# TMS320F280049 register map
Vendor: Texas Instruments; Series: C2000 F28004x; File version: 0.2.0-generated
Registers are 16-bit, read-write, reset 0x0 unless marked. A register's access mark holds for its fields unless they carry their own. Offsets are from the block's base; [hi:lo] are bit positions; {n}, {i} and the like mark numbered series; 'fields as' and 'values as' point back to an identical list.

## EPWM1REGS — EPWM Registers
Base 0x00008000
Same registers: EPWM2REGS 0x00008200, EPWM3REGS 0x00008400, EPWM4REGS 0x00008600, EPWM5REGS 0x00008800, EPWM6REGS 0x00008A00, EPWM7REGS 0x00008C00, EPWM8REGS 0x00008E00
0x00 TBCTL — Time Base Control Register
  [15] FREE_SOFT — Emulation Mode Bits
  [13] PHSDIR — Phase Direction Bit
  [14:12] CLKDIV — Time Base Clock Pre-scaler
  [11:9] HSPCLKDIV — High Speed TBCLK Pre-scaler
  [6] SWFSYNC — Software Force Sync Pulse
  [6:5] SYNCOSEL — Sync Output Select
  [3] PRDLD — Active Period Load
  [2] PHSEN — Phase Load Enable
  [2:1] CTRMODE — Counter Mode
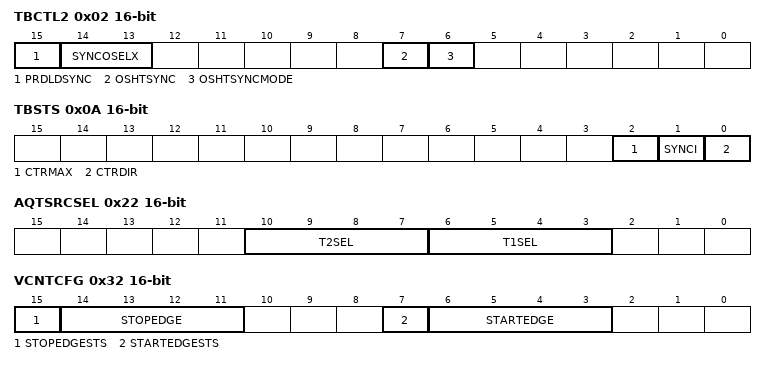
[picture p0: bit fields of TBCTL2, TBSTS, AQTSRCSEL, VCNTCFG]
0x02 TBCTL2 — Time Base Control Register 2
  [15] PRDLDSYNC — PRD Shadow to Active Load on SYNC Event
  [14:13] SYNCOSELX — Syncout selection
  [7] OSHTSYNC — One shot sync
  [6] OSHTSYNCMODE — One shot sync mode
0x08 TBCTR — Time Base Counter Register
  [15] TBCTR — Counter Value
0x0A TBSTS — Time Base Status Register
  [2] CTRMAX — Counter Max Latched Status
  [1] SYNCI — External Input Sync Status
  [0] CTRDIR — Counter Direction Status
0x10 CMPCTL — Counter Compare Control Register
  [14:13] LOADBSYNC — Active Compare B Load on SYNC
  [12:11] LOADASYNC — Active Compare A Load on SYNC
  [9] SHDWBFULL — Compare B Shadow Register Full Status
  [8] SHDWAFULL — Compare A Shadow Register Full Status
  [6] SHDWBMODE — Compare B Register Block Operating Mode
  [4] SHDWAMODE — Compare A Register Block Operating Mode
  [4:3] LOADBMODE — Active Compare B Load
  [2:1] LOADAMODE — Active Compare A Load
0x12 CMPCTL2 — Counter Compare Control Register 2
  [14:13] LOADDSYNC — Active Compare D Load on SYNC
  [12:11] LOADCSYNC — Active Compare C Load on SYNC
  [6] SHDWDMODE — Compare D Block Operating Mode
  [4] SHDWCMODE — Compare C Block Operating Mode
  [4:3] LOADDMODE — Active Compare D load
  [2:1] LOADCMODE — Active Compare C Load
0x18 DBCTL — Dead-Band Generator Control Register
  [15] HALFCYCLE — Half Cycle Clocking Enable
  [14] DEDB_MODE — Dead Band Dual-Edge B Mode Control
  [14:13] OUTSWAP — Dead Band Output Swap Control
  [11] SHDWDBFEDMODE — DBFED Block Operating Mode
  [10] SHDWDBREDMODE — DBRED Block Operating Mode
  [10:9] LOADFEDMODE — Active DBFED Load Mode
  [8:7] LOADREDMODE — Active DBRED Load Mode
  [6:5] IN_MODE — Dead Band Input Select Mode Control
  [4:3] POLSEL — Polarity Select Control
  [2:1] OUT_MODE — Dead Band Output Mode Control
0x1A DBCTL2 — Dead-Band Generator Control Register 2
  [2] SHDWDBCTLMODE — DBCTL Load mode Select
  [2:1] LOADDBCTLMODE — DBCTL Load from Shadow Mode Select
0x20 AQCTL — Action Qualifier Control Register
  [12:11] LDAQBSYNC — AQCTLB Register Load on SYNC
  [10:9] LDAQASYNC — AQCTLA Register Load on SYNC
  [6] SHDWAQBMODE — Action Qualifier B Operating Mode
  [4] SHDWAQAMODE — Action Qualifer A Operating Mode
  [4:3] LDAQBMODE — Action Qualifier B Load Select
  [2:1] LDAQAMODE — Action Qualifier A Load Select
0x22 AQTSRCSEL — Action Qualifier Trigger Event Source Select Register
  [10:7] T2SEL — T2 Event Source Select Bits
  [6:3] T1SEL — T1 Event Source Select Bits
0x28 PCCTL — PWM Chopper Control Register
  [12:10] CHPDUTY — Chopping clock Duty cycle
  [9:7] CHPFREQ — Chopping clock frequency
  [7:4] OSHTWTH — One-shot pulse width
  [0] CHPEN — PWM chopping enable
0x30 VCAPCTL — Valley Capture Control Register
  [10] EDGEFILTDLYSEL — Valley Switching Mode Delay Select
  [11:9] VDELAYDIV — Valley Delay Mode Divide Enable
  [6:4] TRIGSEL — Capture Trigger Select
  [1] VCAPSTART — Valley Capture Start
  [0] VCAPE — Valley Capture mode
0x32 VCNTCFG — Valley Counter Config Register
  [15] STOPEDGESTS — Stop Edge Status Bit
  [14:11] STOPEDGE — Counter Start Edge Selection
  [7] STARTEDGESTS — Start Edge Status Bit
  [6:3] STARTEDGE — Counter Start Edge Selection
0x40 HRCNFG — HRPWM Configuration Register
  [13:12] HRLOADB — ePWMxB Shadow Mode Select Bits
  [10] CTLMODEB — ePWMxB Control Mode Select Bits
  [10:9] EDGMODEB — ePWMxB Edge Mode Select Bits
  [7] SWAPAB — Swap EPWMA and EPWMB Outputs Bit
  [6] AUTOCONV — Autoconversion Bit
  [5] SELOUTB — EPWMB Output Selection Bit
  [5:4] HRLOAD — ePWMxA Shadow Mode Select Bits
  [2] CTLMODE — ePWMxA Control Mode Select Bits
  [2:1] EDGMODE — ePWMxA Edge Mode Select Bits
0x42 HRPWR — HRPWM Power Register
  [15] CALPWRON — Calibration Power On
0x4C HRMSTEP — HRPWM MEP Step Register
  [14:7] HRMSTEP — High Resolution Micro Step Value
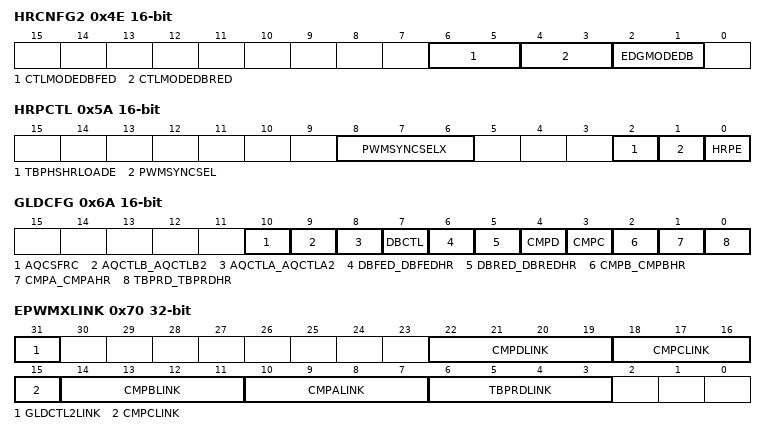
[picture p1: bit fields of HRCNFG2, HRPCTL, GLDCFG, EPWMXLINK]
0x4E HRCNFG2 — HRPWM Configuration 2 Register
  [6:5] CTLMODEDBFED — DBFED Control Mode Select Bits
  [4:3] CTLMODEDBRED — DBRED Control Mode Select Bits
  [2:1] EDGMODEDB — Dead-Band Edge-Mode Select Bits
0x5A HRPCTL — High Resolution Period Control Register
  [8:6] PWMSYNCSELX — EPWMSYNCPER Extended Source Select Bit:
  [2] TBPHSHRLOADE — TBPHSHR Load Enable
  [1] PWMSYNCSEL — EPWMSYNCPER Source Select
  [0] HRPE — High Resolution Period Enable
0x5C TRREM — HRPWM High Resolution Remainder Register
  [15:10] TRREM — HRPWM Remainder Bits
0x68 GLDCTL — Global PWM Load Control Register
  [14:12] GLDCNT — Global Load Strobe Counter Register
  [11:9] GLDPRD — Global Load Strobe Period Select Register
  [5] OSHTMODE — One Shot Load mode control bit
  [7:4] GLDMODE — Shadow to Active Global Load Pulse Selection
  [0] GLD — Global Shadow to Active load event control
0x6A GLDCFG — Global PWM Load Config Register
  [10] AQCSFRC — Global load event configuration for AQCSFRC
  [9] AQCTLB_AQCTLB2 — Global load event configuration for AQCTLB/B2
  [8] AQCTLA_AQCTLA2 — Global load event configuration for AQCTLA/A2
  [7] DBCTL — Global load event configuration for DBCTL
  [6] DBFED_DBFEDHR — Global load event configuration for DBFED:DBFEDHR
  [5] DBRED_DBREDHR — Global load event configuration for DBRED:DBREDHR
  [4] CMPD — Global load event configuration for CMPD
  [3] CMPC — Global load event configuration for CMPC
  [2] CMPB_CMPBHR — Global load event configuration for CMPB:CMPBHR
  [1] CMPA_CMPAHR — Global load event configuration for CMPA:CMPAHR
  [0] TBPRD_TBPRDHR — Global load event configuration for TBPRD:TBPRDHR
0x70 EPWMXLINK 32-bit
  [31] GLDCTL2LINK
  [22:19] CMPDLINK
  [18:15] CMPCLINK
  [14:11] CMPBLINK — CMPB:CMPBHR Link
  [10:7] CMPALINK — CMPA:CMPAHR Link
  [6:3] TBPRDLINK — TBPRD:TBPRDHR Link
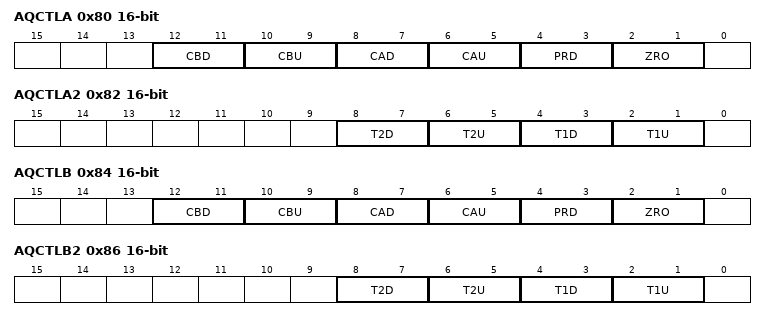
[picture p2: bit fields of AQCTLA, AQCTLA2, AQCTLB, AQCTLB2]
0x80 AQCTLA — Action Qualifier Control Register For Output A
  [12:11] CBD — Action Counter = Compare B Down
  [10:9] CBU — Action Counter = Compare B Up
  [8:7] CAD — Action Counter = Compare A Down
  [6:5] CAU — Action Counter = Compare A Up
  [4:3] PRD — Action Counter = Period
  [2:1] ZRO — Action Counter = Zero
0x82 AQCTLA2 — Additional Action Qualifier Control Register For Output A
  [8:7] T2D — Action when event occurs on T2 in DOWN-Count
  [6:5] T2U — Action when event occurs on T2 in UP-Count
  [4:3] T1D — Action when event occurs on T1 in DOWN-Count
  [2:1] T1U — Action when event occurs on T1 in UP-Count
0x84 AQCTLB — Action Qualifier Control Register For Output B
  fields as AQCTLA
0x86 AQCTLB2 — Additional Action Qualifier Control Register For Output B
  fields as AQCTLA2
0x8E AQSFRC — Action Qualifier Software Force Register
  [8:7] RLDCSF — Reload from Shadow Options
  [5] OTSFB — One-time SW Force A Output
  [5:4] ACTSFB — Action when One-time SW Force B Invoked
  [2] OTSFA — One-time SW Force A Output
  [2:1] ACTSFA — Action when One-time SW Force A Invoked
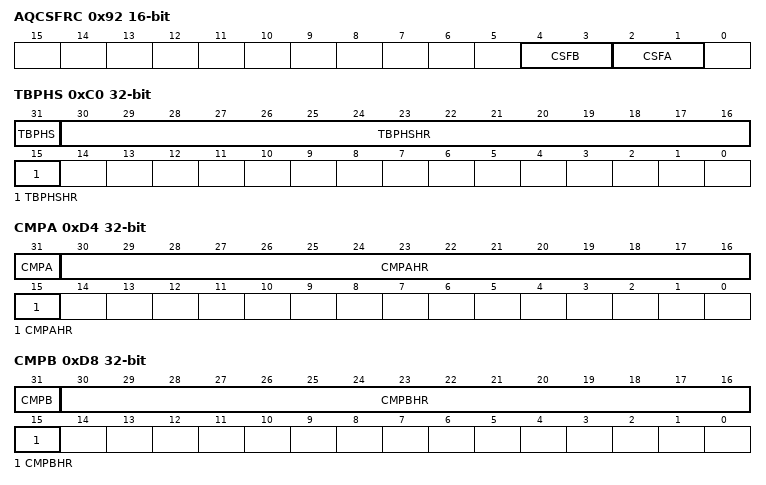
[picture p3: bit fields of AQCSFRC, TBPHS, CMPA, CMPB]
0x92 AQCSFRC — Action Qualifier Continuous S/W Force Register
  [4:3] CSFB — Continuous Software Force on output B
  [2:1] CSFA — Continuous Software Force on output A
0xA0 DBREDHR — Dead-Band Generator Rising Edge Delay High Resolution Mirror Register
  [15] DBREDHR — DBREDHR High Resolution Bits
0xA2 DBRED — Dead-Band Generator Rising Edge Delay High Resolution Mirror Register
  [15:13] DBRED — Rising edge delay value
0xA4 DBFEDHR — Dead-Band Generator Falling Edge Delay High Resolution Register
  [15] DBFEDHR — DBFEDHR High Resolution Bits
0xA6 DBFED — Dead-Band Generator Falling Edge Delay Count Register
  [15:13] DBFED — Falling edge delay value
0xC0 TBPHS 32-bit — Time Base Phase High
  [31] TBPHS — Phase Offset Register
  [30:15] TBPHSHR — Extension Register for HRPWM Phase (8-bits)
0xC4 TBPRDHR — Time Base Period High Resolution Register
  [15] TBPRDHR — High res Time base period register
0xC6 TBPRD — Time Base Period Register
  [15] TBPRD — Time base period register
0xD4 CMPA 32-bit — Counter Compare A Register
  [31] CMPA — Compare A Register
  [30:15] CMPAHR — Compare A HRPWM Extension Register
0xD8 CMPB 32-bit — Compare B Register
  [31] CMPB — Compare B Register
  [30:15] CMPBHR — Compare B High Resolution Bits
0xDE CMPC — Counter Compare C Register
  [15] CMPC — Compare C Register
0xE2 CMPD — Counter Compare D Register
  [15] CMPD — Compare D Register
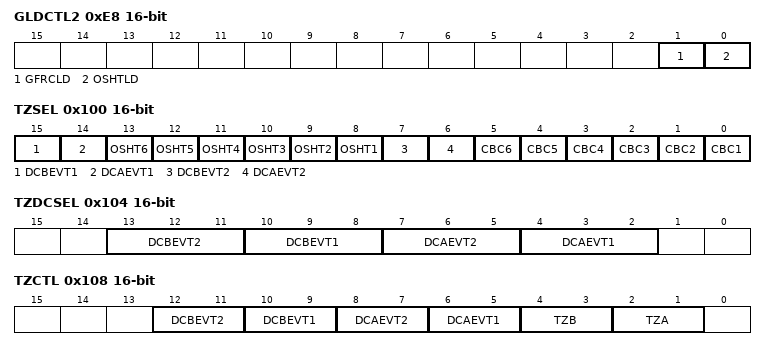
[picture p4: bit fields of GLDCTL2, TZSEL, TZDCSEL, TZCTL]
0xE8 GLDCTL2 — Global PWM Load Control Register 2
  [1] GFRCLD — Force reload event in one shot mode
  [0] OSHTLD — Enable reload event in one shot mode
0xEE SWVDELVAL — Software Valley Mode Delay Register
  [15] SWVDELVAL — Software programmed Valley Delay Value
0x100 TZSEL — Trip Zone Select Register
  [15] DCBEVT1 — One-shot DCBEVT1 select
  [14] DCAEVT1 — One-shot DCAEVT1 select
  [n+7] OSHT{n} (n=1..6) — One-shot TZ{n} select
  [7] DCBEVT2 — DCBEVT2 CBC select
  [6] DCAEVT2 — DCAEVT2 CBC select
  [n-1] CBC{n} (n=1..6) — TZ{n} CBC select
0x104 TZDCSEL — Trip Zone Digital Comparator Select Register
  [13:11] DCBEVT2 — Digital Compare Output B Event 2
  [10:8] DCBEVT1 — Digital Compare Output B Event 1
  [7:5] DCAEVT2 — Digital Compare Output A Event 2
  [4:2] DCAEVT1 — Digital Compare Output A Event 1
0x108 TZCTL — Trip Zone Control Register
  [12:11] DCBEVT2 — EPWMxB action on DCBEVT2
  [10:9] DCBEVT1 — EPWMxB action on DCBEVT1
  [8:7] DCAEVT2 — EPWMxA action on DCAEVT2
  [6:5] DCAEVT1 — EPWMxA action on DCAEVT1
  [4:3] TZB — TZ1 to TZ6 Trip Action On EPWMxB
  [2:1] TZA — TZ1 to TZ6 Trip Action On EPWMxA
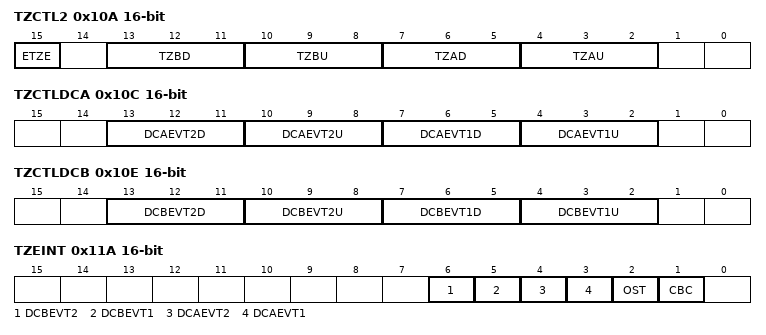
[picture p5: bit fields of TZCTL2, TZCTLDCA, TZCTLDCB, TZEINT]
0x10A TZCTL2 — Additional Trip Zone Control Register
  [15] ETZE — TZCTL2 Enable
  [13:11] TZBD — Trip Action On EPWMxB while Count direction is DOWN
  [10:8] TZBU — Trip Action On EPWMxB while Count direction is UP
  [7:5] TZAD — Trip Action On EPWMxA while Count direction is DOWN
  [4:2] TZAU — Trip Action On EPWMxA while Count direction is UP
0x10C TZCTLDCA — Trip Zone Control Register Digital Compare A
  [13:11] DCAEVT2D — DCAEVT2 Action On EPWMxA while Count direction is DOWN
  [10:8] DCAEVT2U — DCAEVT2 Action On EPWMxA while Count direction is UP
  [7:5] DCAEVT1D — DCAEVT1 Action On EPWMxA while Count direction is DOWN
  [4:2] DCAEVT1U — DCAEVT1 Action On EPWMxA while Count direction is UP
0x10E TZCTLDCB — Trip Zone Control Register Digital Compare B
  [13:11] DCBEVT2D — DCBEVT2 Action On EPWMxA while Count direction is DOWN
  [10:8] DCBEVT2U — DCBEVT2 Action On EPWMxA while Count direction is UP
  [7:5] DCBEVT1D — DCBEVT1 Action On EPWMxA while Count direction is DOWN
  [4:2] DCBEVT1U — DCBEVT1 Action On EPWMxA while Count direction is UP
0x11A TZEINT — Trip Zone Enable Interrupt Register
  [6] DCBEVT2 — Digital Compare B Event 2 Int Enable
  [5] DCBEVT1 — Digital Compare B Event 1 Int Enable
  [4] DCAEVT2 — Digital Compare A Event 2 Int Enable
  [3] DCAEVT1 — Digital Compare A Event 1 Int Enable
  [2] OST — Trip Zones One Shot Int Enable
  [1] CBC — Trip Zones Cycle By Cycle Int Enable
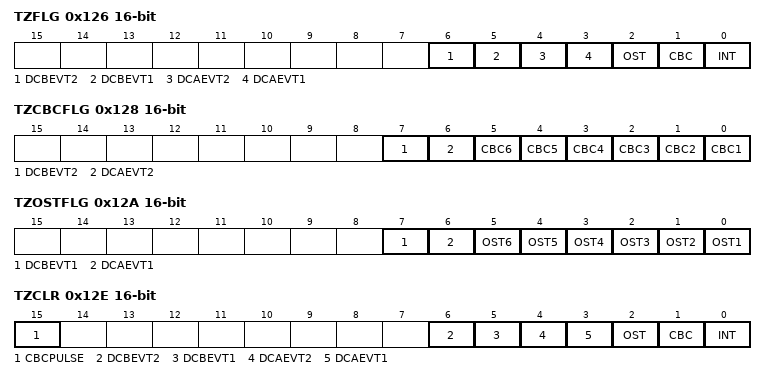
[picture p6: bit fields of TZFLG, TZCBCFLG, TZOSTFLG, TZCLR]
0x126 TZFLG — Trip Zone Flag Register
  [6] DCBEVT2 — Digital Compare B Event 2 Flag
  [5] DCBEVT1 — Digital Compare B Event 1 Flag
  [4] DCAEVT2 — Digital Compare A Event 2 Flag
  [3] DCAEVT1 — Digital Compare A Event 1 Flag
  [2] OST — Trip Zones One Shot Flag
  [1] CBC — Trip Zones Cycle By Cycle Flag
  [0] INT — Global Int Status Flag
0x128 TZCBCFLG — Trip Zone CBC Flag Register
  [7] DCBEVT2 — Latched Status Flag for Digital Compare Output B Event 2
  [6] DCAEVT2 — Latched Status Flag for Digital Compare Output A Event 2
  [n-1] CBC{n} (n=1..6) — Latched Status Flag for CBC{n} Trip Latch
0x12A TZOSTFLG — Trip Zone OST Flag Register
  [7] DCBEVT1 — Latched Status Flag for Digital Compare Output B Event 1
  [6] DCAEVT1 — Latched Status Flag for Digital Compare Output A Event 1
  [n-1] OST{n} (n=1..6) — Latched Status Flag for OST{n} Trip Latch
0x12E TZCLR — Trip Zone Clear Register
  [15] CBCPULSE — Clear Pulse for CBC Trip Latch
  [6] DCBEVT2 — DCBEVT2 Flag Clear
  [5] DCBEVT1 — DCBEVT1 Flag Clear
  [4] DCAEVT2 — DCAEVT2 Flag Clear
  [3] DCAEVT1 — DCAVET1 Flag Clear
  [2] OST — One-Shot Flag Clear
  [1] CBC — Cycle-By-Cycle Flag Clear
  [0] INT — Global Interrupt Clear Flag
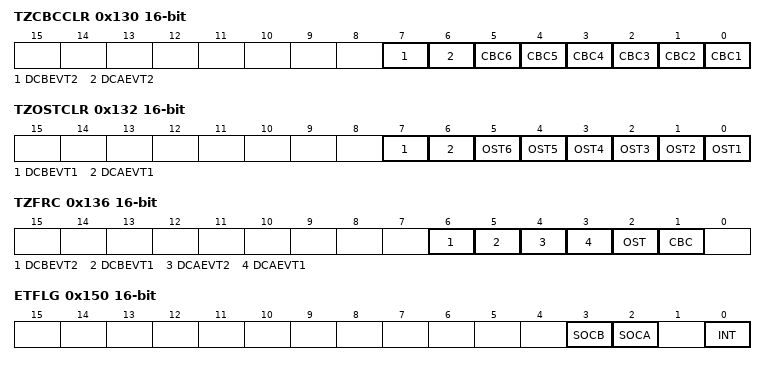
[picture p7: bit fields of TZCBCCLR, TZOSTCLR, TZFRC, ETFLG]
0x130 TZCBCCLR — Trip Zone CBC Clear Register
  [7] DCBEVT2 — Clear Flag for DCBEVT2 selected for CBC
  [6] DCAEVT2 — Clear Flag forDCAEVT2 selected for CBC
  [n-1] CBC{n} (n=1..6) — Clear Flag for Cycle-By-Cycle (CBC{n}) Trip Latch
0x132 TZOSTCLR — Trip Zone OST Clear Register
  [7] DCBEVT1 — Clear Flag for DCBEVT1 selected for OST
  [6] DCAEVT1 — Clear Flag for DCAEVT1 selected for OST
  [n-1] OST{n} (n=1..6) — Clear Flag for Oneshot (OST{n}) Trip Latch
0x136 TZFRC — Trip Zone Force Register
  [6] DCBEVT2 — Force Digital Compare B Event 2
  [5] DCBEVT1 — Force Digital Compare B Event 1
  [4] DCAEVT2 — Force Digital Compare A Event 2
  [3] DCAEVT1 — Force Digital Compare A Event 1
  [2] OST — Force Trip Zones One Shot Event
  [1] CBC — Force Trip Zones Cycle By Cycle Event
0x148 ETSEL — Event Trigger Selection Register
  [15] SOCBEN — Start of Conversion B Enable
  [15:14] SOCBSEL — Start of Conversion B Select
  [11] SOCAEN — Start of Conversion A Enable
  [12:10] SOCASEL — Start of Conversion A Select
  [6] INTSELCMP — EPWMxINT Compare Select
  [5] SOCBSELCMP — EPWMxSOCB Compare Select
  [4] SOCASELCMP — EPWMxSOCA Compare Select
  [3] INTEN — EPWMxINTn Enable
  [4:2] INTSEL — EPWMxINTn Select
0x14C ETPS — Event Trigger Pre-Scale Register
  [15] SOCBCNT — EPWMxSOCB Counter
  [14:13] SOCBPRD — EPWMxSOCB Period Select
  [12:11] SOCACNT — EPWMxSOCA Counter Register
  [10:9] SOCAPRD — EPWMxSOCA Period Select
  [5] SOCPSSEL — EPWMxSOC A/B Pre-Scale Selection Bits
  [4] INTPSSEL — EPWMxINTn Pre-Scale Selection Bits
  [4:3] INTCNT — EPWMxINTn Counter Register
  [2:1] INTPRD — EPWMxINTn Period Select
0x150 ETFLG — Event Trigger Flag Register
  [3] SOCB — EPWMxSOCB Flag
  [2] SOCA — EPWMxSOCA Flag
  [0] INT — EPWMxINTn Flag
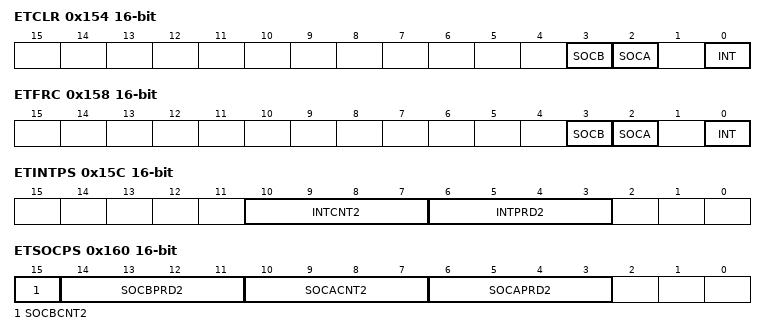
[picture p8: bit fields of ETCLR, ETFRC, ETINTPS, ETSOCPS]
0x154 ETCLR — Event Trigger Clear Register
  [3] SOCB — EPWMxSOCB Clear
  [2] SOCA — EPWMxSOCA Clear
  [0] INT — EPWMxINTn Clear
0x158 ETFRC — Event Trigger Force Register
  [3] SOCB — EPWMxSOCB Force
  [2] SOCA — EPWMxSOCA Force
  [0] INT — EPWMxINTn Force
0x15C ETINTPS — Event-Trigger Interrupt Pre-Scale Register
  [10:7] INTCNT2 — EPWMxINTn Counter Register
  [6:3] INTPRD2 — EPWMxINTn Period Select
0x160 ETSOCPS — Event-Trigger SOC Pre-Scale Register
  [15] SOCBCNT2 — EPWMxSOCB Counter Register
  [14:11] SOCBPRD2 — EPWMxSOCB Period Select
  [10:7] SOCACNT2 — EPWMxSOCA Counter Register
  [6:3] SOCAPRD2 — EPWMxSOCA Period Select
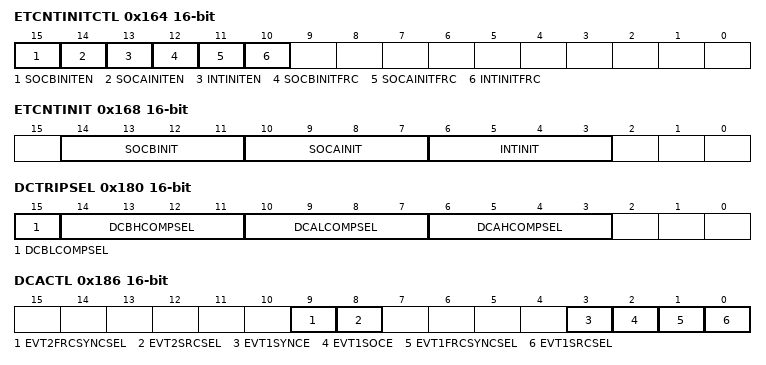
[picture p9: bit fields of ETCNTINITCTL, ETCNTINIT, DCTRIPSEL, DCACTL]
0x164 ETCNTINITCTL — Event-Trigger Counter Initialization Control Register
  [15] SOCBINITEN — EPWMxSOCB Counter Initialization Enable
  [14] SOCAINITEN — EPWMxSOCA Counter Initialization Enable
  [13] INTINITEN — EPWMxINT Counter Initialization Enable
  [12] SOCBINITFRC — EPWMxSOCB Counter Initialization Force
  [11] SOCAINITFRC — EPWMxSOCA Counter Initialization Force
  [10] INTINITFRC — EPWMxINT Counter Initialization Force
0x168 ETCNTINIT — Event-Trigger Counter Initialization Register
  [14:11] SOCBINIT — EPWMxSOCB Counter Initialization Bits
  [10:7] SOCAINIT — EPWMxSOCA Counter Initialization Bits
  [6:3] INTINIT — EPWMxINT Counter Initialization Bits
0x180 DCTRIPSEL — Digital Compare Trip Select Register
  [15] DCBLCOMPSEL — Digital Compare B Low COMP Input Select
  [14:11] DCBHCOMPSEL — Digital Compare B High COMP Input Select
  [10:7] DCALCOMPSEL — Digital Compare A Low COMP Input Select
  [6:3] DCAHCOMPSEL — Digital Compare A High COMP Input Select
0x186 DCACTL — Digital Compare A Control Register
  [9] EVT2FRCSYNCSEL — DCAEVT2 Force Sync Signal
  [8] EVT2SRCSEL — DCAEVT2 Source Signal
  [3] EVT1SYNCE — DCAEVT1 SYNC Enable
  [2] EVT1SOCE — DCAEVT1 SOC Enable
  [1] EVT1FRCSYNCSEL — DCAEVT1 Force Sync Signal
  [0] EVT1SRCSEL — DCAEVT1 Source Signal
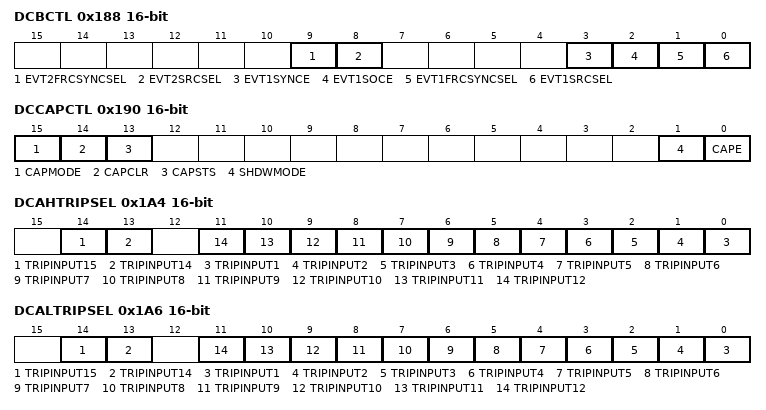
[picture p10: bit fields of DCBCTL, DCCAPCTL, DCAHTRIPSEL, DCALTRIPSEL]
0x188 DCBCTL — Digital Compare B Control Register
  [9] EVT2FRCSYNCSEL — DCBEVT2 Force Sync Signal
  [8] EVT2SRCSEL — DCBEVT2 Source Signal
  [3] EVT1SYNCE — DCBEVT1 SYNC Enable
  [2] EVT1SOCE — DCBEVT1 SOC Enable
  [1] EVT1FRCSYNCSEL — DCBEVT1 Force Sync Signal
  [0] EVT1SRCSEL — DCBEVT1 Source Signal
0x18E DCFCTL — Digital Compare Filter Control Register
  [15] EDGESTATUS
  [14:12] EDGECOUNT
  [10:9] EDGEMODE
  [6] EDGEFILTSEL — Edge Filter Select
  [6:5] PULSESEL — Pulse Select for Blanking and Capture Alignment
  [3] BLANKINV — Blanking Window Inversion
  [2] BLANKE — Blanking Enable/Disable
  [2:1] SRCSEL — Filter Block Signal Source Select
0x190 DCCAPCTL — Digital Compare Capture Control Register
  [15] CAPMODE — Counter Capture Mode
  [14] CAPCLR — DC Capture Latched Status Clear Flag
  [13] CAPSTS — Latched Status Flag for Capture Event
  [1] SHDWMODE — Counter Capture Mode
  [0] CAPE — Counter Capture Enable
0x192 DCFOFFSET — Digital Compare Filter Offset Register
  [15] DCFOFFSET — Blanking Offset
0x194 DCFOFFSETCNT — Digital Compare Filter Offset Counter Register
  [15] DCFOFFSETCNT — Blanking Offset Counter
0x196 DCFWINDOW — Digital Compare Filter Window Register
  [15] DCFWINDOW
0x198 DCFWINDOWCNT — Digital Compare Filter Window Counter Register
  [15] DCFWINDOWCNT
0x19E DCCAP — Digital Compare Counter Capture Register
  [15] DCCAP — Time Base Counter Capture Register
0x1A4 DCAHTRIPSEL — Digital Compare AH Trip Select
  [14] TRIPINPUT15 — Trip Input 15 Select to DCAH Mux
  [13] TRIPINPUT14 — Trip Input 14 Select to DCAH Mux
  [n-1] TRIPINPUT{n} (n=1..12) — Trip Input {n} Select to DCAH Mux
0x1A6 DCALTRIPSEL — Digital Compare AL Trip Select
  [14] TRIPINPUT15 — Trip Input 15 Select to DCAL Mux
  [13] TRIPINPUT14 — Trip Input 14 Select to DCAL Mux
  [n-1] TRIPINPUT{n} (n=1..12) — Trip Input {n} Select to DCAL Mux
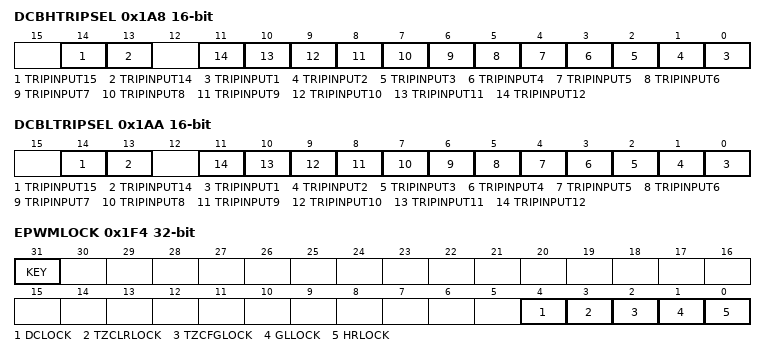
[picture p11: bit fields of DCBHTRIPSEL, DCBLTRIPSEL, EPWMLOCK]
0x1A8 DCBHTRIPSEL — Digital Compare BH Trip Select
  [14] TRIPINPUT15 — Trip Input 15 Select to DCBH Mux
  [13] TRIPINPUT14 — Trip Input 14 Select to DCBH Mux
  [n-1] TRIPINPUT{n} (n=1..12) — Trip Input {n} Select to DCBH Mux
0x1AA DCBLTRIPSEL — Digital Compare BL Trip Select
  [14] TRIPINPUT15 — Trip Input 15 Select to DCBL Mux
  [13] TRIPINPUT14 — Trip Input 14 Select to DCBL Mux
  [n-1] TRIPINPUT{n} (n=1..12) — Trip Input {n} Select to DCBL Mux
0x1F4 EPWMLOCK 32-bit
  [31] KEY — Key to write to this register
  [4] DCLOCK — Digital Compare Register Set Lock
  [3] TZCLRLOCK — TripZone Clear Register Set Lock
  [2] TZCFGLOCK — TripZone Register Set Lock
  [1] GLLOCK — Global Load Register Set Lock
  [0] HRLOCK — HRPWM Register Set Lock
0x1FA HWVDELVAL — Hardware Valley Mode Delay Register
  [15] HWVDELVAL — Hardware programmed Valley Delay Value
0x1FC VCNTVAL — Hardware Valley Counter Register
  [15] VCNTVAL — Valley Counter Value
